# MKW36Z4 register map
Vendor: NXP Semiconductors; Series: Kinetis_W; File version: 1.6
CPU: CM0PLUS r0p0, little endian, no MPU, no FPU, VTOR, 2 interrupt priority bits
Registers are 16-bit, read-write, no defined reset value unless marked. A register's access mark holds for its fields unless they carry their own. Offsets are from the block's base; [hi:lo] are bit positions; {n}, {i} and the like mark numbered series; 'fields as' and 'values as' point back to an identical list.

## XCVR_ANALOG
Base 0x4005C500
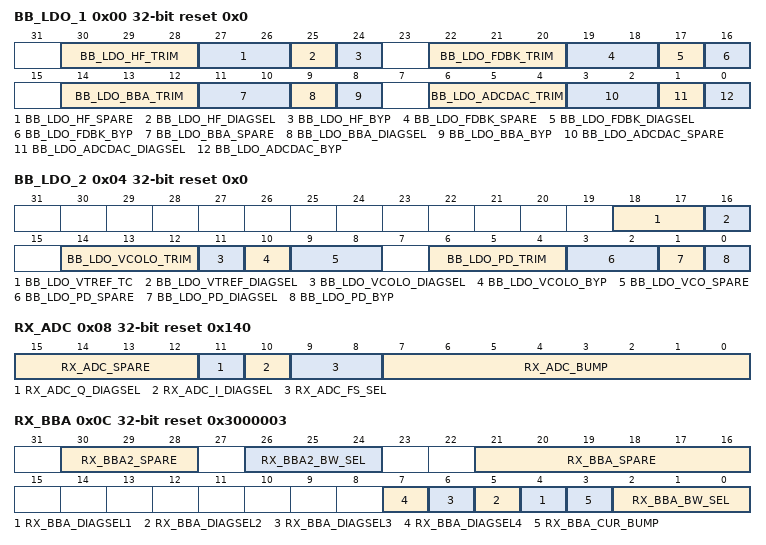
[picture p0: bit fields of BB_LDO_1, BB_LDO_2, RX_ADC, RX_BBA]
0x00 BB_LDO_1 32-bit reset 0x0 — RF Analog Baseband LDO Control 1
  [30:28] BB_LDO_HF_TRIM — rmap_bb_ldo_hf_trim[2:0]
    0=1.20 V ( Default ); 1=1.25 V; 2=1.28 V; 3=1.33 V; 4=1.40 V; 5=1.44 V; 6=1.50 V; 7=1.66 V
  [27:26] BB_LDO_HF_SPARE — rmap_bb_ldo_hf_spare[1:0]
  [25] BB_LDO_HF_DIAGSEL — rmap_bb_ldo_hf_diagsel
    0=Diag disable; 1=Diag enable
  [24] BB_LDO_HF_BYP — rmap_bb_ldo_hf_byp
    0=Bypass disabled; 1=Bypass enabled
  [22:20] BB_LDO_FDBK_TRIM — rmap_bb_ldo_fdbk_trim[2:0]
    0=1.2/1.176 V ( Default ); 1=1.138/1.115 V; 2=1.085/1.066 V; 3=1.04/1.025 V; 4=1.28/1.25 V; 5=1.4/1.35 V; 6=1.55/1.4 V; 7=1.78/1.4 V
  [19:18] BB_LDO_FDBK_SPARE — rmap_bb_ldo_fdbk_spare[1:0]
  [17] BB_LDO_FDBK_DIAGSEL — rmap_bb_ldo_fdbk_diagsel
    0=Diag disable; 1=Diag enable
  [16] BB_LDO_FDBK_BYP — rmap_bb_ldo_fdbk_byp
    0=Bypass disabled; 1=Bypass enabled
  [14:12] BB_LDO_BBA_TRIM — rmap_bb_ldo_bba_trim[2:0]
    values as BB_LDO_HF_TRIM
  [11:10] BB_LDO_BBA_SPARE — rmap_bb_ldo_bba_spare[1:0]
  [9] BB_LDO_BBA_DIAGSEL — rmap_bb_ldo_bba_diagsel
    0=Diag disable; 1=Diag enable
  [8] BB_LDO_BBA_BYP — rmap_bb_ldo_bba_byp
    0=Bypass disabled; 1=Bypass enabled
  [6:4] BB_LDO_ADCDAC_TRIM — rmap_bb_ldo_adcdac_trim[2:0]
    values as BB_LDO_HF_TRIM
  [3:2] BB_LDO_ADCDAC_SPARE — rmap_bb_ldo_adcdac_spare[1:0]
  [1] BB_LDO_ADCDAC_DIAGSEL — rmap_bb_ldo_adcdac_diagsel
    0=Diag disable; 1=Diag enable
  [0] BB_LDO_ADCDAC_BYP — rmap_bb_ldo_adcdac_byp
    0=Bypass disabled; 1=Bypass enabled
0x04 BB_LDO_2 32-bit reset 0x0 — RF Analog Baseband LDO Control 2
  [18:17] BB_LDO_VTREF_TC — rmap_bb_ldo_vtref_tc[1:0]
    0=1.117/1.176 V; 1=1.134/1.188 V; 2=1.10/1.162 V; 3=1.09/1.152 V
  [16] BB_LDO_VTREF_DIAGSEL — rmap_bb_ldo_vtref_diagsel
    0=Diag disable; 1=Diag enable
  [14:12] BB_LDO_VCOLO_TRIM — rmap_bb_ldo_vcolo_trim[2:0]
    0=1.138/1.117 V ( Default ); 1=1.076/1.058 V; 2=1.027/1.012 V; 3=0.98/0.97 V; 4=1.22/1.19 V; 5=1.33/1.3 V; 6=1.5/1.4 V; 7=1.82/1.4 V
  [11] BB_LDO_VCOLO_DIAGSEL — rmap_bb_ldo_vcolo_diagsel
    0=Diag disable; 1=Diag enable
  [10] BB_LDO_VCOLO_BYP — rmap_bb_ldo_vcolo_byp
    0=Bypass disabled; 1=Bypass enabled
  [9:8] BB_LDO_VCO_SPARE — rmap_bb_ldo_vco_spare[1:0]
  [6:4] BB_LDO_PD_TRIM — rmap_bb_ldo_pd_trim[2:0]
    values as BB_LDO_1.BB_LDO_HF_TRIM
  [3:2] BB_LDO_PD_SPARE — rmap_bb_ldo_pd_spare[1:0]
  [1] BB_LDO_PD_DIAGSEL — rmap_bb_ldo_pd_diagsel
    0=Diag disable; 1=Diag enable
  [0] BB_LDO_PD_BYP — rmap_bb_ldo_pd_byp
    0=Bypass disabled; 1=Bypass enabled
0x08 RX_ADC 32-bit reset 0x140 — RF Analog ADC Control
  [15:12] RX_ADC_SPARE — rmap_rx_adc_spare[3:0]
  [11] RX_ADC_Q_DIAGSEL — rmap_rx_adc_q_diagsel
  [10] RX_ADC_I_DIAGSEL — rmap_rx_adc_i_diagsel
  [9:8] RX_ADC_FS_SEL — rmap_rx_adc_fs_sel[1:0]
    0=52MHz (2x26MHz); 1=64MHz (2x32MHz); 2=+13% of 64MHz; 3=- 11% of 64MHz
  [7:0] RX_ADC_BUMP — rmap_rx_adc_bump[7:0]
0x0C RX_BBA 32-bit reset 0x3000003 — RF Analog BBA Control
  [30:28] RX_BBA2_SPARE — rmap_rx_bba2_spare[2:0]
  [26:24] RX_BBA2_BW_SEL — rmap_bba2_bw_sel[2:0]
    0=1000K; 1=900K; 2=800K; 3=700K Default; 4=600K; 5=500K
  [21:16] RX_BBA_SPARE — rmap_rx_bba_spare[5:0]
    0=600mV (Default); 1=675mV; 2=450mV; 3=525mV
  [n+3] RX_BBA_DIAGSEL{n} (n=1..4) — rmap_rx_bba_diagsel{n}
    0=Diag disable; 1=Diag enable
  [3] RX_BBA_CUR_BUMP — rmap_rx_bba_cur_bump
  [2:0] RX_BBA_BW_SEL — rmap_rx_bba_bw_sel[2:0]
    0=1000K; 1=900K; 2=800K; 3=700K Default; 4=600K; 5=500K
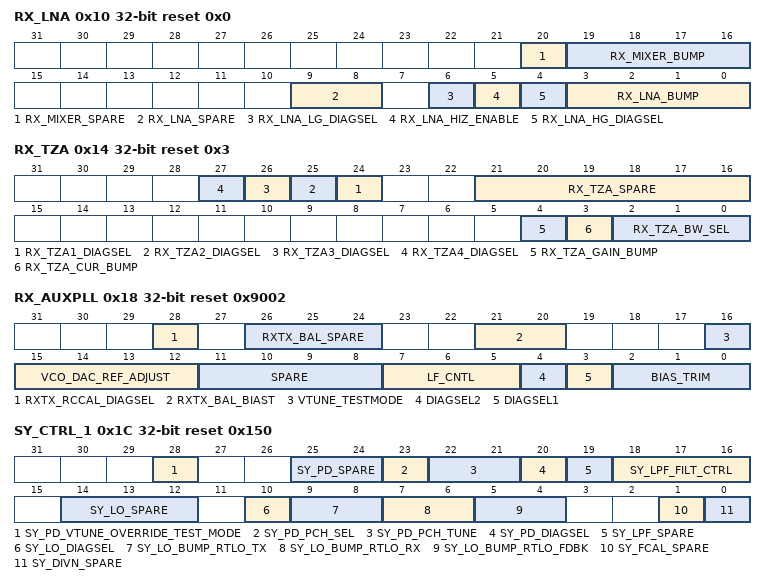
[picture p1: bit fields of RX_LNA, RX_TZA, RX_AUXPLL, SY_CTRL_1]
0x10 RX_LNA 32-bit reset 0x0 — RF Analog LNA Control
  [20] RX_MIXER_SPARE — rmap_rx_mixer_spare
  [19:16] RX_MIXER_BUMP — rmap_rx_mixer_bump[3:0]
    0=825mV (Default); 1=750mV; 2=900mV; 3=975mV
  [9:8] RX_LNA_SPARE — rmap_rx_lna_spare[1:0]
  [6] RX_LNA_LG_DIAGSEL — rmap_rx_lna_lg_diagsel
  [5] RX_LNA_HIZ_ENABLE — rmap_rx_lna_hiZ_enable
  [4] RX_LNA_HG_DIAGSEL — rmap_rx_lna_hg_diagsel
  [3:0] RX_LNA_BUMP — rmap_rx_lna_bump[3:0]
    0=Default; 1=-25%; 2=+50%; 3=+25%; 4=CM 480mV; 8=CM 600mV; 12=CM 660mV
0x14 RX_TZA 32-bit reset 0x3 — RF Analog TZA Control
  [n+23] RX_TZA{n}_DIAGSEL (n=1..4) — rmap_rx_tza{n}_diagsel
    0=Diag disable; 1=Diag enable
  [21:16] RX_TZA_SPARE — rmap_rx_tza_spare[5:0]
    0=600mV (Default); 1=675mV; 2=450mV; 3=525mV
  [4] RX_TZA_GAIN_BUMP — rmap_rx_tza_gain_bump
  [3] RX_TZA_CUR_BUMP — rmap_rx_tza_cur_bump
  [2:0] RX_TZA_BW_SEL — rmap_rx_tza_bw_sel[2:0]
    0=1000K; 1=900K; 2=800K; 3=700K Default; 4=600K; 5=500K
0x18 RX_AUXPLL 32-bit reset 0x9002 — RF Analog Aux PLL Control
  [28] RXTX_RCCAL_DIAGSEL — rmap_rxtx_rccal_diagsel
  [26:24] RXTX_BAL_SPARE — rmap_rxtx_bal_spare[2:0]
  [21:20] RXTX_BAL_BIAST — rmap_rxtx_bal_biast[1:0]
    0=0.6; 1=0.4; 2=0.9; 3=1.2
  [16] VTUNE_TESTMODE — rmap_rxtx_auxpll_vtune_testmode
  [15:12] VCO_DAC_REF_ADJUST — rmap_rxtx_auxpll_vco_dac_ref_adjust[3:0]
  [11:8] SPARE — rmap_rxtx_auxpll_spare[3:0]
  [7:5] LF_CNTL — rmap_rxtx_auxpll_lf_cntl[2:0]
  [4] DIAGSEL2 — rmap_rxtx_auxpll_diagsel2
  [3] DIAGSEL1 — rmap_rxtx_auxpll_diagsel1
  [2:0] BIAS_TRIM — rmap_rxtx_auxpll_bias_trim[2:0]
0x1C SY_CTRL_1 32-bit reset 0x150 — RF Analog Synthesizer Control 1
  [28] SY_PD_VTUNE_OVERRIDE_TEST_MODE — rmap_sy_pd_vtune_override_test_mode
  [25:24] SY_PD_SPARE — rmap_sy_pd_spare[1:0]
    0=Default ;; 1=PD output is pulled down
  [23] SY_PD_PCH_SEL — rmap_sy_pd_pch_sel
    0=inverter based precharge; 1=resistor divider based precharge
  [22:21] SY_PD_PCH_TUNE — rmap_sy_pd_pch_tune[1:0]
  [20] SY_PD_DIAGSEL — rmap_sy_pd_diagsel
  [19] SY_LPF_SPARE — rmap_sy_lpf_spare
  [18:16] SY_LPF_FILT_CTRL — rmap_sy_lpf_filt_ctrl[2:0]
  [14:12] SY_LO_SPARE — rmap_sy_lo_spare[2:0]
  [10] SY_LO_DIAGSEL — rmap_sy_lo_diagsel
    0=Diag disable; 1=Diag enable
  [9:8] SY_LO_BUMP_RTLO_TX — rmap_sy_lo_bump_rtlo_tx[1:0]
    0=1.071/1.065 V; 1=1.092/1.090 V; 2=1.099/1.098 V; 3=1.10/1.1 V
  [7:6] SY_LO_BUMP_RTLO_RX — rmap_sy_lo_bump_rtlo_rx[1:0]
    0=1.051/1.037 V; 1=1.082/1.075 V; 2=1.092/1.088 V; 3=1.098/1.094 V
  [5:4] SY_LO_BUMP_RTLO_FDBK — rmap_sy_lo_bump_rtlo_fdbk[1:0]
    0=1.045 V; 1=1.084 V; 2=1.097 V; 3=1.10 V
  [1] SY_FCAL_SPARE — rmap_sy_fcal_spare
  [0] SY_DIVN_SPARE — rmap_sy_divn_spare
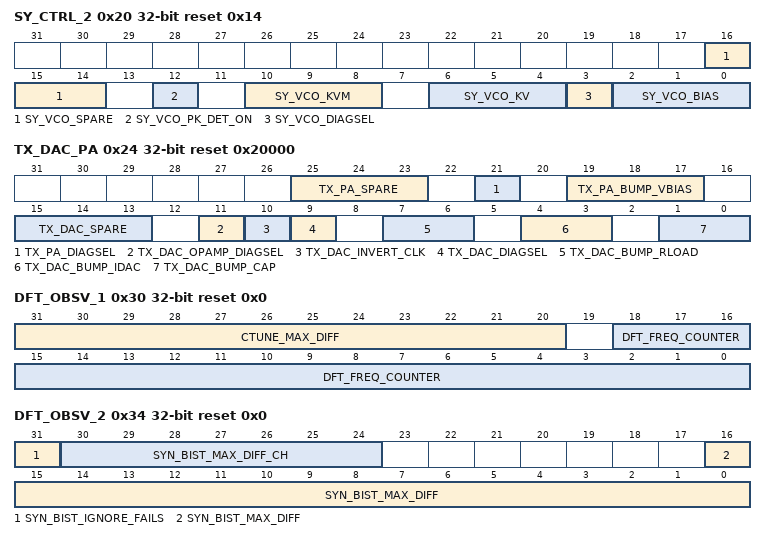
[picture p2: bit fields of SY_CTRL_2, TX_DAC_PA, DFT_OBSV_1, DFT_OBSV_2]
0x20 SY_CTRL_2 32-bit reset 0x14 — RF Analog Synthesizer Control 2
  [16:14] SY_VCO_SPARE — rmap_sy_vco_spare[2:0]
  [12] SY_VCO_PK_DET_ON — rmap_sy_vco_pk_det_on
    1=Enable; 0=Disable
  [10:8] SY_VCO_KVM — rmap_sy_vco_kvm[2:0]
    0=10MHz/V; 1=20MHz/V; 2=30MHz/V; {v}=40MHz/V (v=3..7)
  [6:4] SY_VCO_KV — rmap_sy_vco_kv[2:0]
    0=50MHz/V; 1=60MHz/V; 2=70MHz/V; {v}=80MHz/V (v=3..7)
  [3] SY_VCO_DIAGSEL — rmap_sy_vco_diagsel
    1=Diag enable; 0=Diag disable
  [2:0] SY_VCO_BIAS — rmap_sy_vco_bias[2:0]
    0=0.97V; 1=1.033V; 2=1.06V; 3=1.07V; 4=1.08V; 5=1.085V; 6=1.090V; 7=1.095V
0x24 TX_DAC_PA 32-bit reset 0x20000 — RF Analog TX HPM DAC and PA Control
  [25:23] TX_PA_SPARE — rmap_tx_pa_spare[2:0]
  [21] TX_PA_DIAGSEL — rmap_tx_pa_diagsel
  [19:17] TX_PA_BUMP_VBIAS — rmap_tx_pa_bump_vbias[2:0]
    0=0.557; 1=0.651; 2=0.741; 3=0.822; 4=0.590; 5=0.683; 6=0.771; 7=0.850
  [15:13] TX_DAC_SPARE — rmap_tx_dac_spare[2:0]
  [11] TX_DAC_OPAMP_DIAGSEL — rmap_tx_dac_opamp_diagsel
    0=Disable Diag; 1=Enable Diag
  [10] TX_DAC_INVERT_CLK — rmap_tx_dac_invert_clk
  [9] TX_DAC_DIAGSEL — rmap_tx_dac_diagsel
    0=Disable Diag; 1=Enable Diag
  [7:6] TX_DAC_BUMP_RLOAD — rmap_tx_dac_bump_rload[1:0]
    0=3.12 kohms(default); 1=2.34 kohms; 2=3.9 kohms; 3=4.6 kohms
  [4:3] TX_DAC_BUMP_IDAC — rmap_tx_dac_bump_idac[1:0]
    0=250nA(default); 1=207nA; 2=312nA; 3=415nA
  [1:0] TX_DAC_BUMP_CAP — rmap_tx_dac_bump_cap[1:0]
    0=1pF(default); 1=1.5pF; 2=1.5pF; 3=2pF
0x28 BALUN_TX 32-bit reset 0x724B6D — RF Analog Balun TX Mode Control
  [23:0] RXTX_BAL_TX_CODE — Balun Tuning Cap Settings in Transmit Mode
0x2C BALUN_RX 32-bit reset 0x49372D — RF Analog Balun RX Mode Control
  [23:0] RXTX_BAL_RX_CODE — Balun Tuning Cap Settings in Receive Mode
0x30 DFT_OBSV_1 32-bit ro reset 0x0 — RF Analog DFT Observation Register 1
  [31:20] CTUNE_MAX_DIFF — Maximum Frequency Count Difference found by the Coarse Tune BIST
  [18:0] DFT_FREQ_COUNTER — VCO Frequency Counter Value
0x34 DFT_OBSV_2 32-bit reset 0x0 — RF Analog DFT Observation Register 2
  [31] SYN_BIST_IGNORE_FAILS — PLL Frequency Synthesizer BIST Ignore Fails
  [30:24] SYN_BIST_MAX_DIFF_CH ro — PLL Frequency Synthesizer BIST Worst Channel
  [16:0] SYN_BIST_MAX_DIFF ro — PLL Frequency Synthesizer BIST Worst Frequency Count
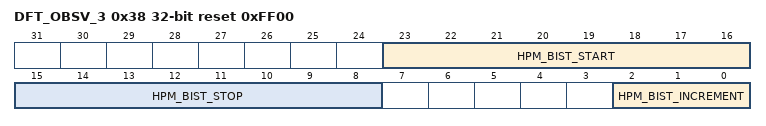
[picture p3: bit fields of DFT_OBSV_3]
0x38 DFT_OBSV_3 32-bit reset 0xFF00 — RF Analog DFT Observation Register 3
  [23:16] HPM_BIST_START — HPM BIST Start Value
  [15:8] HPM_BIST_STOP — HPM BIST Stop Value
  [2:0] HPM_BIST_INCREMENT — HPM BIST Increment Value
